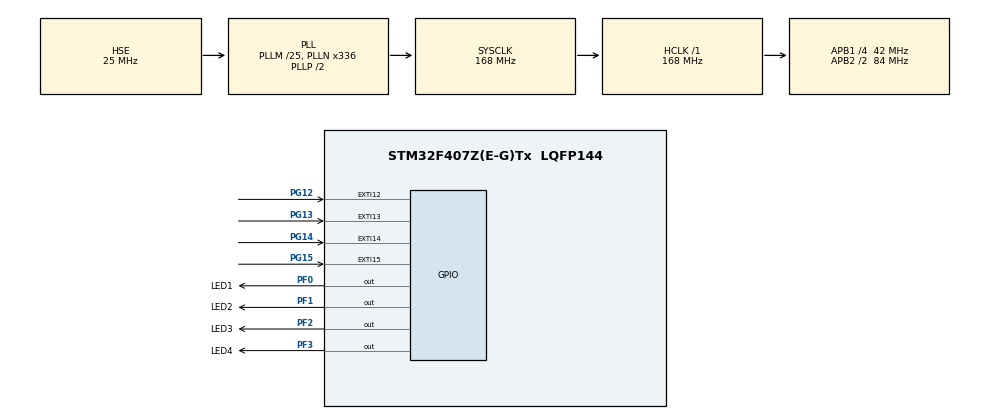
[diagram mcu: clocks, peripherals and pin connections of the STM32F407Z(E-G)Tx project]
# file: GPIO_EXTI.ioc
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Mcu.Family=STM32F4
Mcu.Name=STM32F407Z(E-G)Tx
Mcu.Package=LQFP144
NVIC.EXTI15_10_IRQn=true\:3\:0\:true\:false\:true\:true\:true\:true
NVIC.PriorityGroup=NVIC_PRIORITYGROUP_4
PF0.GPIO_Label=LED1
PF0.PinState=GPIO_PIN_SET
PF0.Signal=GPIO_Output
PF1.GPIO_Label=LED2
PF1.PinState=GPIO_PIN_SET
PF1.Signal=GPIO_Output
PF2.GPIO_Label=LED3
PF2.PinState=GPIO_PIN_SET
PF2.Signal=GPIO_Output
PF3.GPIO_Label=LED4
PF3.PinState=GPIO_PIN_SET
PF3.Signal=GPIO_Output
PG12.GPIO_ModeDefaultEXTI=GPIO_MODE_IT_RISING_FALLING
PG12.Signal=GPXTI12
PG13.GPIO_ModeDefaultEXTI=GPIO_MODE_IT_RISING_FALLING
PG13.Signal=GPXTI13
PG14.GPIO_ModeDefaultEXTI=GPIO_MODE_IT_RISING_FALLING
PG14.Signal=GPXTI14
PG15.GPIO_ModeDefaultEXTI=GPIO_MODE_IT_RISING_FALLING
PG15.Signal=GPXTI15
PH0-OSC_IN.Mode=HSE-External-Oscillator
PH0-OSC_IN.Signal=RCC_OSC_IN
PH1-OSC_OUT.Mode=HSE-External-Oscillator
PH1-OSC_OUT.Signal=RCC_OSC_OUT
ProjectManager.HeapSize=0x200
ProjectManager.StackSize=0x400
ProjectManager.TargetToolchain=STM32CubeIDE
RCC.48MHZClocksFreq_Value=84000000
RCC.AHBFreq_Value=168000000
RCC.APB1CLKDivider=RCC_HCLK_DIV4
RCC.APB1Freq_Value=42000000
RCC.APB1TimFreq_Value=84000000
RCC.APB2CLKDivider=RCC_HCLK_DIV2
RCC.APB2Freq_Value=84000000
RCC.APB2TimFreq_Value=168000000
RCC.CortexFreq_Value=168000000
RCC.HCLKFreq_Value=168000000
RCC.HSE_VALUE=25000000
RCC.HSI_VALUE=16000000
RCC.LSE_VALUE=32768
RCC.PLLM=25
RCC.PLLN=336
RCC.PLLSourceVirtual=RCC_PLLSOURCE_HSE
RCC.SYSCLKFreq_VALUE=168000000
RCC.SYSCLKSource=RCC_SYSCLKSOURCE_PLLCLK
RCC.VCOOutputFreq_Value=336000000
board=custom

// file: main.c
/* USER CODE BEGIN Header */
/**
  ******************************************************************************
  * @file           : main.c
  * @brief          : Main program body
  ******************************************************************************
  * @attention
  *
  * Copyright (c) 2022 STMicroelectronics.
  * All rights reserved.
  *
  * This software is licensed under terms that can be found in the LICENSE file
  * in the root directory of this software component.
  * If no LICENSE file comes with this software, it is provided AS-IS.
  *
  ******************************************************************************
  */
/* USER CODE END Header */
#include "main.h"

void SystemClock_Config(void);
static void MX_GPIO_Init(void);

int main(void)
{

  /* MCU Configuration--------------------------------------------------------*/

  /* Reset of all peripherals, Initializes the Flash interface and the Systick. */
  HAL_Init();

  /* Configure the system clock */
  SystemClock_Config();

  /* Initialize all configured peripherals */
  MX_GPIO_Init();

  /* Infinite loop */
  while (1)
  {

  }
}

void SystemClock_Config(void)
{
  RCC_OscInitTypeDef RCC_OscInitStruct = {0};
  RCC_ClkInitTypeDef RCC_ClkInitStruct = {0};

  /** Configure the main internal regulator output voltage
  */
  __HAL_RCC_PWR_CLK_ENABLE();
  __HAL_PWR_VOLTAGESCALING_CONFIG(PWR_REGULATOR_VOLTAGE_SCALE1);

  /** Initializes the RCC Oscillators according to the specified parameters
  * in the RCC_OscInitTypeDef structure.
  */
  RCC_OscInitStruct.OscillatorType = RCC_OSCILLATORTYPE_HSE;
  RCC_OscInitStruct.HSEState = RCC_HSE_ON;
  RCC_OscInitStruct.PLL.PLLState = RCC_PLL_ON;
  RCC_OscInitStruct.PLL.PLLSource = RCC_PLLSOURCE_HSE;
  RCC_OscInitStruct.PLL.PLLM = 25;
  RCC_OscInitStruct.PLL.PLLN = 336;
  RCC_OscInitStruct.PLL.PLLP = RCC_PLLP_DIV2;
  RCC_OscInitStruct.PLL.PLLQ = 4;
  if (HAL_RCC_OscConfig(&RCC_OscInitStruct) != HAL_OK)
  {
    Error_Handler();
  }

  /** Initializes the CPU, AHB and APB buses clocks
  */
  RCC_ClkInitStruct.ClockType = RCC_CLOCKTYPE_HCLK|RCC_CLOCKTYPE_SYSCLK
                              |RCC_CLOCKTYPE_PCLK1|RCC_CLOCKTYPE_PCLK2;
  RCC_ClkInitStruct.SYSCLKSource = RCC_SYSCLKSOURCE_PLLCLK;
  RCC_ClkInitStruct.AHBCLKDivider = RCC_SYSCLK_DIV1;
  RCC_ClkInitStruct.APB1CLKDivider = RCC_HCLK_DIV4;
  RCC_ClkInitStruct.APB2CLKDivider = RCC_HCLK_DIV2;

  if (HAL_RCC_ClockConfig(&RCC_ClkInitStruct, FLASH_LATENCY_5) != HAL_OK)
  {
    Error_Handler();
  }
}

static void MX_GPIO_Init(void)
{
  GPIO_InitTypeDef GPIO_InitStruct = {0};

  /* GPIO Ports Clock Enable */
  __HAL_RCC_GPIOF_CLK_ENABLE();
  __HAL_RCC_GPIOH_CLK_ENABLE();
  __HAL_RCC_GPIOG_CLK_ENABLE();

  /*Configure GPIO pin Output Level */
  HAL_GPIO_WritePin(GPIOF, GPIO_PIN_0|GPIO_PIN_1|GPIO_PIN_2|GPIO_PIN_3, GPIO_PIN_SET);

  /*Configure GPIO pins : PF0 PF1 PF2 PF3 */
  GPIO_InitStruct.Pin = GPIO_PIN_0|GPIO_PIN_1|GPIO_PIN_2|GPIO_PIN_3;
  GPIO_InitStruct.Mode = GPIO_MODE_OUTPUT_PP;
  GPIO_InitStruct.Pull = GPIO_NOPULL;
  GPIO_InitStruct.Speed = GPIO_SPEED_FREQ_LOW;
  HAL_GPIO_Init(GPIOF, &GPIO_InitStruct);

  /*Configure GPIO pins : PG12 PG13 PG14 PG15 */
  GPIO_InitStruct.Pin = GPIO_PIN_12|GPIO_PIN_13|GPIO_PIN_14|GPIO_PIN_15;
  GPIO_InitStruct.Mode = GPIO_MODE_IT_RISING_FALLING;
  GPIO_InitStruct.Pull = GPIO_NOPULL;
  HAL_GPIO_Init(GPIOG, &GPIO_InitStruct);

  /* EXTI interrupt init*/
  HAL_NVIC_SetPriority(EXTI15_10_IRQn, 3, 0);
  HAL_NVIC_EnableIRQ(EXTI15_10_IRQn);

}

/* USER CODE BEGIN 4 */
void HAL_GPIO_EXTI_Callback(uint16_t GPIO_Pin)
{

  /* Prevent unused argument(s) compilation warning */
	HAL_Delay(10);
  if(HAL_GPIO_ReadPin(GPIOG, GPIO_PIN_12) && GPIO_Pin == GPIO_PIN_12){
	  HAL_GPIO_TogglePin(GPIOF, GPIO_PIN_0);
  }
  if(HAL_GPIO_ReadPin(GPIOG, GPIO_PIN_13) && GPIO_Pin == GPIO_PIN_13){
	  HAL_GPIO_TogglePin(GPIOF, GPIO_PIN_1);
  }
  if(HAL_GPIO_ReadPin(GPIOG, GPIO_PIN_14) && GPIO_Pin == GPIO_PIN_14){
	  HAL_GPIO_TogglePin(GPIOF, GPIO_PIN_2);
  }
  if(HAL_GPIO_ReadPin(GPIOG, GPIO_PIN_15) && GPIO_Pin == GPIO_PIN_15){
	  HAL_GPIO_TogglePin(GPIOF, GPIO_PIN_3);
  }
  HAL_Delay(100);
  /* NOTE: This function Should not be modified, when the callback is needed,
           the HAL_GPIO_EXTI_Callback could be implemented in the user file
   */
}
/* USER CODE END 4 */

void Error_Handler(void)
{
  __disable_irq();
  while (1)
  {
  }
}
